# max32690 register map
Vendor: Maxim-Integrated; Series: ARMCM4; File version: 1.0
CPU: CM4 r2p1, little endian, MPU, FPU, 3 interrupt priority bits
Registers are 32-bit, read-write, reset 0x0 unless marked. A register's access mark holds for its fields unless they carry their own. Offsets are from the block's base; [hi:lo] are bit positions; {n}, {i} and the like mark numbered series; 'fields as' and 'values as' point back to an identical list.

## ICC0 — Instruction Cache Controller Registers
Base 0x4002A000
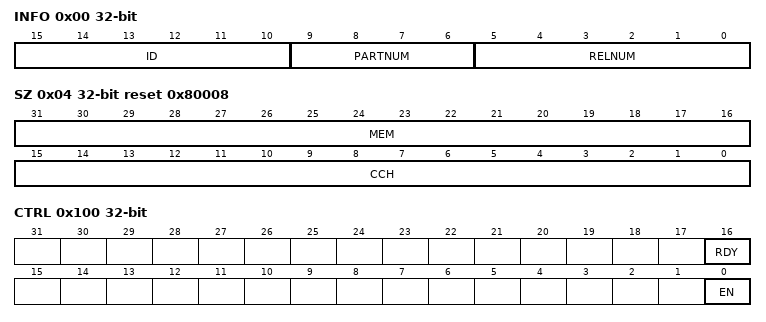
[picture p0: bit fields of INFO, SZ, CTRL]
0x00 INFO ro — Cache ID Register.
  [15:10] ID — Cache ID. This field reflects the value of the C_ID_CACHEID configuration parameter.
  [9:6] PARTNUM — Part Number. This field reflects the value of C_ID_PART_NUMBER configuration parameter.
  [5:0] RELNUM — Release Number. Identifies the RTL release version.
0x04 SZ ro reset 0x80008 — Memory Configuration Register.
  [31:16] MEM — Main Memory Size. Indicates the total size, in units of 128 Kbytes, of code memory accessible to the cache controller.
  [15:0] CCH — Cache Size. Indicates total size in Kbytes of cache.
0x100 CTRL — Cache Control and Status Register.
  [16] RDY ro — Cache Ready flag. Cleared by hardware when at any time the cache as a whole is invalidated (including a system reset). When this bit is 0, the cache is effectively in bypass mode (instruction fetches will come from main memory or from the line fill buffer). Set by hardware when the invalidate operation is complete and the cache is ready.
    0=notReady; 1=ready
  [0] EN — Cache Enable. Controls whether the cache is bypassed or is in use. Changing the state of this bit will cause the instruction cache to be flushed and its contents invalidated.
    0=dis (Cache Bypassed. Instruction data is stored in the line fill buffer but is not written to main cache memory array.); 1=en (Cache Enabled.)
0x700 INVALIDATE — Invalidate All Registers.
  [31:0] INVALID — Invalidate.

## LPCMP — Low Power Comparator
Base 0x40088000
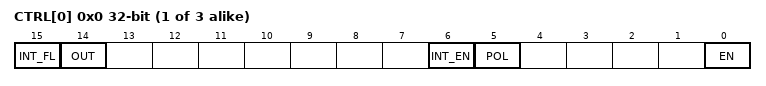
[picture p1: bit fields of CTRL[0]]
{0x0+4i} CTRL[{i}] (i=0..2) — Comparator Control Register.
  [15] INT_FL — IRQ Flag
  [14] OUT — Raw Compartor Input.
  [6] INT_EN — IRQ Enable.
  [5] POL — Polarity Select
  [0] EN — Comparator Enable.

## LPGCR — Low Power Global Control.
Base 0x40080000
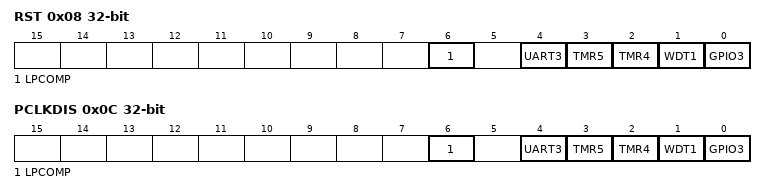
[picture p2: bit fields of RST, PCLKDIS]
0x08 RST — Low Power Reset Register.
  [all] fields
    0=reset_done (Reset complete.); 1=busy (Starts Reset or indicates reset in progress.)
  [6] LPCOMP — Low Power Comparator Reset.
  [4] UART3 — Low Power UART 3 Reset.
  [3] TMR5 — Low Power Timer 5 Reset.
  [2] TMR4 — Low Power Timer 4 Reset.
  [1] WDT1 — Low Power Watchdog Timer 1 Reset.
  [0] GPIO3 — Low Power GPIO 3 Reset.
0x0C PCLKDIS — Low Power Peripheral Clock Disable Register.
  [all] fields
    0=en (enable it.); 1=dis (disable it.)
  [6] LPCOMP — Low Power Comparator Clock Disable.
  [4] UART3 — Low Power UART 3 Clock Disable.
  [3] TMR5 — Low Power Timer 5 Clock Disable.
  [2] TMR4 — Low Power Timer 4 Clock Disable.
  [1] WDT1 — Low Power Watchdog 1 Clock Disable.
  [0] GPIO3 — Low Power GPIO 3 Clock Disable.

## MCR — Misc Control.
Base 0x40006C00
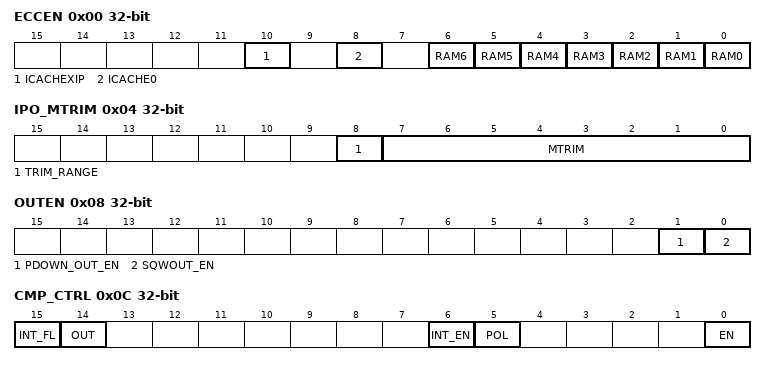
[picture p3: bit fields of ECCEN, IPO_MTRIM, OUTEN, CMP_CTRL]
0x00 ECCEN — ECC Enable Register
  [all] fields
    0=dis (disabled.); 1=en (enabled.)
  [10] ICACHEXIP — ECC ICACHE XIP Enable.
  [8] ICACHE0 — ECC ICACHE0 Enable.
  [n] RAM{n} (n=0..6) — ECC System RAM{n} Enable.
0x04 IPO_MTRIM — IPO Manual Register
  [8] TRIM_RANGE — Trim Range Select.
  [7:0] MTRIM — Manual Trim Value.
0x08 OUTEN — Output Enable Register
  [1] PDOWN_OUT_EN — Power Down Output Enable.
  [0] SQWOUT_EN — Square Wave Output Enable.
0x0C CMP_CTRL — Comparator Control Register.
  [15] INT_FL — IRQ Flag
  [14] OUT — Comparator Output State.
  [6] INT_EN — IRQ Enable.
  [5] POL — Polarity Select
  [0] EN — Comparator Enable.
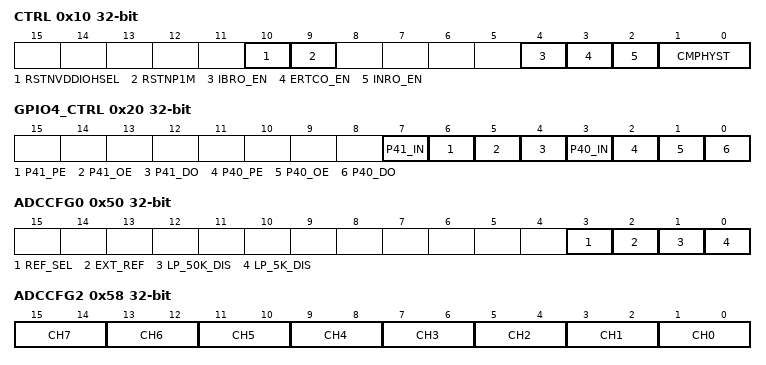
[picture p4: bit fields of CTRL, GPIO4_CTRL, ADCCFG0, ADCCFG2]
0x10 CTRL — Miscellaneous Control Register.
  [10] RSTNVDDIOHSEL — RSTNVFFIOHSEL
  [9] RSTNP1M
  [4] IBRO_EN — IBRO Enable.
  [3] ERTCO_EN — ERTCO Enable.
  [2] INRO_EN — INRO Enable.
  [1:0] CMPHYST — Comparator HYST.
0x20 GPIO4_CTRL — GPIO4 Pin Control Register.
  [7] P41_IN — GPIO4 Pin 1 Input Status.
  [6] P41_PE — GPIO4 Pin 1 Pull-up Enable.
  [5] P41_OE — GPIO4 Pin 1 Output Enable.
  [4] P41_DO — GPIO4 Pin 1 Data Output.
  [3] P40_IN — GPIO4 Pin 0 Input Status.
  [2] P40_PE — GPIO4 Pin 0 Pull-up Enable.
  [1] P40_OE — GPIO4 Pin 0 Output Enable.
  [0] P40_DO — GPIO4 Pin 0 Data Output.
0x40 CWD0 — Code Word Data0
  [31:0] data — Code word Data0 the register retains its value while vregi supply present
0x44 CWD1 — Code Word Data1
  fields as CWD0
0x50 ADCCFG0 — ADC Config 0
  [3] REF_SEL — Internal Reference Select Option
  [2] EXT_REF — External Reference Select Option
  [1] LP_50K_DIS — Disable 50K divider optionin low power modes
  [0] LP_5K_DIS — Disable 5K divider optionin low power modes
0x54 ADCCFG1 — ADC Config 1
  [12:0] CHX_PU_DYN — ADC PU dynamic control
0x58 ADCCFG2 — ADC Config 2
  [all] fields
    0=div1; 1=div2_5k (5k ohom); 2=div2_50k (50k ohom)
  [2n+1:2n] CH{n} (n=0..7) — Divider option for ADC input channel {n}
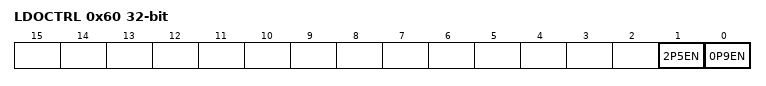
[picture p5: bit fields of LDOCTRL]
0x60 LDOCTRL — LDO Control
  [1] 2P5EN — LDO 2.5V Enable
  [0] 0P9EN — LDO 0.9V Enable
